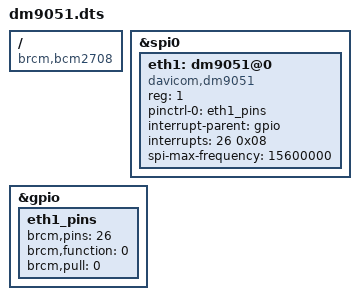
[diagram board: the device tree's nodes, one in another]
// Overlay for the davicom dm9051 Ethernet Controller
/dts-v1/;
/plugin/;

/ {
    compatible = "brcm,bcm2708";

    fragment@0 {
        target = <&spi0>;
        __overlay__ {
            /* needed to avoid dtc warning */
            #address-cells = <1>;
            #size-cells = <0>;

            status = "okay";

            eth1: dm9051@0{
                compatible = "davicom,dm9051";
                reg = <1>; /* SPI0.x:: CS0: pin 24 GPIO 8,  CS1: pin 26 gpio 7*/
                pinctrl-names = "default";
                pinctrl-0 = <&eth1_pins>;
                interrupt-parent = <&gpio>;
                interrupts = <26 0x08>; /* 0x08, level low (8) | level high (4) | falling edge(2) | raising edge(1) */
                spi-max-frequency = <15600000>; /* <31200000> */
                status = "okay";
            };
        };
    };
	
    fragment@1 {
        target = <&gpio>;

        __overlay__ {
            eth1_pins: eth1_pins {
                brcm,pins = <26>;
                brcm,function = <0>; /* in */
                brcm,pull = <0>; /* none */
            };
        };
    };
    
	
	// lock spidev on spi0
	/*fragment@2 {
		target = <&spidev0>;
		__overlay__ {
			status = "disabled";
		};
	};*/

    // disable spi-dev on spi0.0
    /*fragment@2 {
        target-path = "spi1/spidev@2"; 

        __dormant__ {
            status = "disabled";
        };
    };*/

    __overrides__ {
        int_pin = <&eth1>, "interrupts:0",
                  <&eth1_pins>, "brcm,pins:0";
        speed   = <&eth1>, "spi-max-frequency:0";
    };

    // add symbols__by JJ__
	__symbols__ {
		eth1 = "/fragment@0/__overlay__/dm9051@0";
		eth1_pins = "/fragment@1/__overlay__/eth1_pins";
	};
};
